VERSION ""

NS_ :

BS_:

BU_: PRBMS

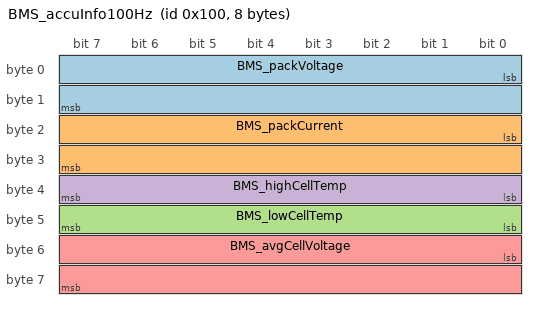
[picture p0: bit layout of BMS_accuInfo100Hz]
BO_ 256 BMS_accuInfo100Hz: 8 PRBMS
 SG_ BMS_packVoltage : 0|16@1+ (0.1,0) [0|6553.5] "V" Vector__XXX
 SG_ BMS_packCurrent : 16|16@1+ (0.1,0) [0|6553.5] "A" Vector__XXX
 SG_ BMS_lowCellTemp : 40|8@1+ (1,0) [0|255] "C" Vector__XXX
 SG_ BMS_highCellTemp : 32|8@1+ (1,0) [0|255] "C" Vector__XXX
 SG_ BMS_avgCellVoltage : 48|16@1+ (0.001,0) [0|0] "V" Vector__XXX

BA_DEF_  "BusType" STRING ;
BA_DEF_DEF_  "BusType" "CAN";
